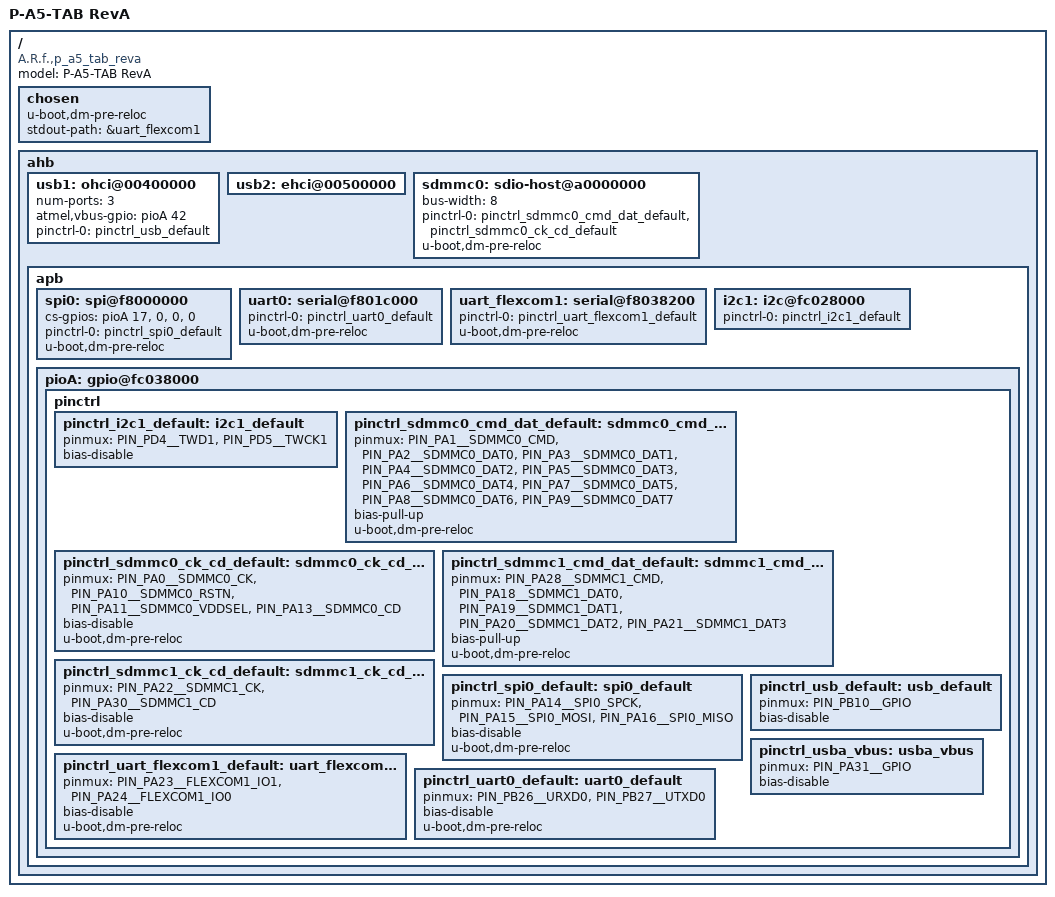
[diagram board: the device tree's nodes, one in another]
/dts-v1/;
#include <dt-bindings/gpio/gpio.h>
#include "sama5d2.dtsi"
#include "sama5d2-pinfunc.h"
/ {
	model = "P-A5-TAB RevA";
	compatible = "A.R.f.,p_a5_tab_reva", "atmel,sama5d2", "atmel,sama5";

	chosen {
		u-boot,dm-pre-reloc;
		stdout-path = &uart_flexcom1;
	};

	ahb {

		usb1: ohci@00400000 {
			num-ports = <3>;
			atmel,vbus-gpio = <&pioA 42 0>;
			pinctrl-names = "default";
			pinctrl-0 = <&pinctrl_usb_default>;
			status = "okay";
		};

		usb2: ehci@00500000 {
			status = "okay";
		};

		sdmmc0: sdio-host@a0000000 {
			bus-width = <8>;
			pinctrl-names = "default";
			pinctrl-0 = <&pinctrl_sdmmc0_cmd_dat_default &pinctrl_sdmmc0_ck_cd_default>;
			status = "okay";
			u-boot,dm-pre-reloc;
		};

		apb {
			spi0: spi@f8000000 {
				cs-gpios = <&pioA 17 0>, <0>, <0>, <0>;
				pinctrl-names = "default";
				pinctrl-0 = <&pinctrl_spi0_default>;
				status = "okay";
				u-boot,dm-pre-reloc;
			};

			uart0: serial@f801c000 { 
				pinctrl-names = "default";
				pinctrl-0 = <&pinctrl_uart0_default>;
				status = "okay";
				u-boot,dm-pre-reloc;
			};
			
			uart_flexcom1: serial@f8038200 {
				pinctrl-names = "default";
				pinctrl-0 = <&pinctrl_uart_flexcom1_default>;
				status = "okay";
				u-boot,dm-pre-reloc;
			};
			
			i2c1: i2c@fc028000 {
				pinctrl-names = "default";
				pinctrl-0 = <&pinctrl_i2c1_default>;
				status = "okay";
			};

			pioA: gpio@fc038000 {
				pinctrl {
					pinctrl_i2c1_default: i2c1_default {
						pinmux = <PIN_PD4__TWD1>,
							 <PIN_PD5__TWCK1>;
						bias-disable;
					};

					pinctrl_sdmmc0_cmd_dat_default: sdmmc0_cmd_dat_default {
						pinmux = <PIN_PA1__SDMMC0_CMD>,
							 <PIN_PA2__SDMMC0_DAT0>,
							 <PIN_PA3__SDMMC0_DAT1>,
							 <PIN_PA4__SDMMC0_DAT2>,
							 <PIN_PA5__SDMMC0_DAT3>,
							 <PIN_PA6__SDMMC0_DAT4>,
							 <PIN_PA7__SDMMC0_DAT5>,
							 <PIN_PA8__SDMMC0_DAT6>,
							 <PIN_PA9__SDMMC0_DAT7>;
						bias-pull-up;
						u-boot,dm-pre-reloc;
					};

					pinctrl_sdmmc0_ck_cd_default: sdmmc0_ck_cd_default {
						pinmux = <PIN_PA0__SDMMC0_CK>,
							 <PIN_PA10__SDMMC0_RSTN>,
							 <PIN_PA11__SDMMC0_VDDSEL>,
							 <PIN_PA13__SDMMC0_CD>;
						bias-disable;
						u-boot,dm-pre-reloc;
					};

					pinctrl_sdmmc1_cmd_dat_default: sdmmc1_cmd_dat_default {
						pinmux = <PIN_PA28__SDMMC1_CMD>,
							 <PIN_PA18__SDMMC1_DAT0>,
							 <PIN_PA19__SDMMC1_DAT1>,
							 <PIN_PA20__SDMMC1_DAT2>,
							 <PIN_PA21__SDMMC1_DAT3>;
						bias-pull-up;
						u-boot,dm-pre-reloc;
					};

					pinctrl_sdmmc1_ck_cd_default: sdmmc1_ck_cd_default {
						pinmux = <PIN_PA22__SDMMC1_CK>,
							 <PIN_PA30__SDMMC1_CD>;
						bias-disable;
						u-boot,dm-pre-reloc;
					};

					pinctrl_spi0_default: spi0_default {
						pinmux = <PIN_PA14__SPI0_SPCK>,
							 <PIN_PA15__SPI0_MOSI>,
							 <PIN_PA16__SPI0_MISO>;
						bias-disable;
						u-boot,dm-pre-reloc;
					};

					pinctrl_uart_flexcom1_default: uart_flexcom1_default {
						pinmux = <PIN_PA23__FLEXCOM1_IO1>,
							 <PIN_PA24__FLEXCOM1_IO0>;
						bias-disable;
						u-boot,dm-pre-reloc;
					};
					
					pinctrl_uart0_default: uart0_default {
						pinmux = <PIN_PB26__URXD0>,
							 <PIN_PB27__UTXD0>;
						bias-disable;
						u-boot,dm-pre-reloc;
					};

					pinctrl_usb_default: usb_default {
						pinmux = <PIN_PB10__GPIO>;
						bias-disable;
					};

					pinctrl_usba_vbus: usba_vbus {
						pinmux = <PIN_PA31__GPIO>;
						bias-disable;
					};
				};
			};
		};
	};
};
